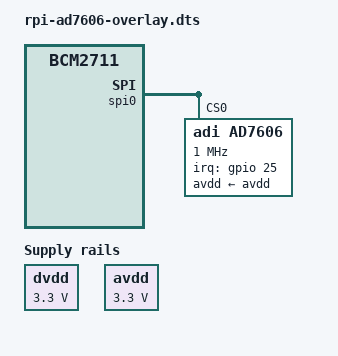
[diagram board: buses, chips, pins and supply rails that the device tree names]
/dts-v1/;
/plugin/;

/ {
	compatible =  "brcm,bcm2835", "brcm,bcm2708", "brcm,bcm2709", "brcm,bcm2711";

	fragment@0 {
		target-path = "/";
		__overlay__ {
			dvdd: fixedregulator@0 {
				compatible = "regulator-fixed";
				regulator-name = "fixed-supply";
				regulator-min-microvolt = <3300000>;
				regulator-max-microvolt = <3300000>;
				regulator-boot-on;
			};
		};
	};

	fragment@1 {
		target-path = "/";
		__overlay__ {
			avdd: fixedregulator@1 {
				compatible = "regulator-fixed";
				regulator-name = "fixed-supply2";
				regulator-min-microvolt = <3300000>;
				regulator-max-microvolt = <3300000>;
				regulator-boot-on;
			};
		};
	};
	
	fragment@2 {
		target = <&spi0>;
		__overlay__ {
			#address-cells = <1>;
			#size-cells = <0>;
			status = "okay";
			compatible = "brcm,bcm2835-spi";
			ad7606@0 {
				compatible = "adi,ad7606";
				reg = <0>;
				spi-max-frequency = <1000000>;
				spi-cpol;
				spi-cpha;
				#interrupt-cells = <2>;
				interrupts = <25 0x2>;
				interrupt-parent = <&gpio>;
				avdd-supply = <&avdd>;

				adi,sw-mode;
			};
		};
	};	
	
	fragment@3 {
		target = <&spidev0>;
		__overlay__ {
			status = "disabled";
		};
	};

	fragment@4 {
		target = <&spidev1>;
		__overlay__ {
			status = "disabled";
		};
	};
};

